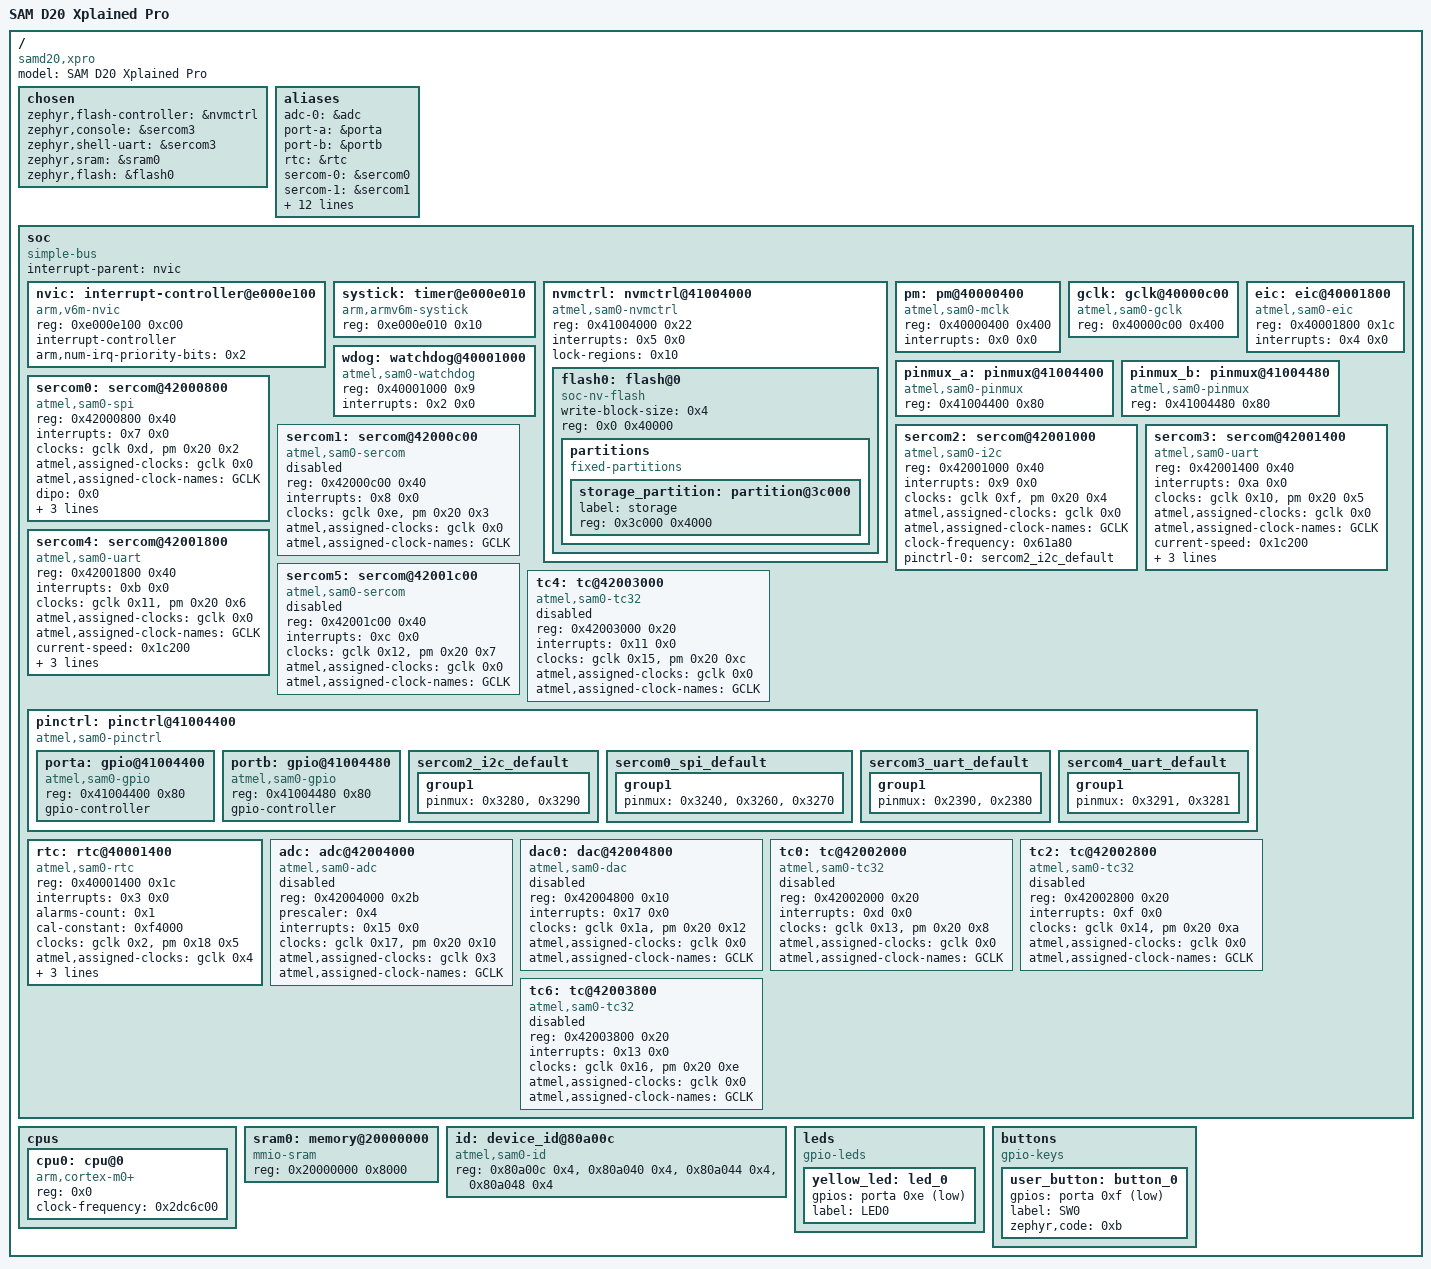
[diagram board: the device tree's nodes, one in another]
/dts-v1/;

/* node '/' defined in zephyr/dts/common/skeleton.dtsi:9 */
/ {
	#address-cells = < 0x1 >;       /* in zephyr/dts/common/skeleton.dtsi:10 */
	#size-cells = < 0x1 >;          /* in zephyr/dts/common/skeleton.dtsi:11 */
	model = "SAM D20 Xplained Pro"; /* in zephyr/boards/atmel/sam0/samd20_xpro/samd20_xpro.dts:16 */
	compatible = "samd20,xpro",
	             "atmel,samd20j18",
	             "atmel,samd20";    /* in zephyr/boards/atmel/sam0/samd20_xpro/samd20_xpro.dts:17 */

	/* node '/chosen' defined in zephyr/dts/common/skeleton.dtsi:13 */
	chosen {
		zephyr,flash-controller = &nvmctrl; /* in zephyr/dts/arm/atmel/samd2x.dtsi:37 */
		zephyr,console = &sercom3;          /* in zephyr/boards/atmel/sam0/samd20_xpro/samd20_xpro.dts:20 */
		zephyr,shell-uart = &sercom3;       /* in zephyr/boards/atmel/sam0/samd20_xpro/samd20_xpro.dts:21 */
		zephyr,sram = &sram0;               /* in zephyr/boards/atmel/sam0/samd20_xpro/samd20_xpro.dts:22 */
		zephyr,flash = &flash0;             /* in zephyr/boards/atmel/sam0/samd20_xpro/samd20_xpro.dts:23 */
	};

	/* node '/aliases' defined in zephyr/dts/common/skeleton.dtsi:15 */
	aliases {
		adc-0 = &adc;        /* in zephyr/dts/arm/atmel/samd2x.dtsi:17 */
		port-a = &porta;     /* in zephyr/dts/arm/atmel/samd2x.dtsi:19 */
		port-b = &portb;     /* in zephyr/dts/arm/atmel/samd2x.dtsi:20 */
		rtc = &rtc;          /* in zephyr/dts/arm/atmel/samd2x.dtsi:22 */
		sercom-0 = &sercom0; /* in zephyr/dts/arm/atmel/samd2x.dtsi:24 */
		sercom-1 = &sercom1; /* in zephyr/dts/arm/atmel/samd2x.dtsi:25 */
		sercom-2 = &sercom2; /* in zephyr/dts/arm/atmel/samd2x.dtsi:26 */
		sercom-3 = &sercom3; /* in zephyr/dts/arm/atmel/samd2x.dtsi:27 */
		sercom-4 = &sercom4; /* in zephyr/dts/arm/atmel/samd2x.dtsi:28 */
		sercom-5 = &sercom5; /* in zephyr/dts/arm/atmel/samd2x.dtsi:29 */
		tc-4 = &tc4;         /* in zephyr/dts/arm/atmel/samd2x.dtsi:31 */
		watchdog0 = &wdog;   /* in zephyr/dts/arm/atmel/samd2x.dtsi:33 */
		tc-0 = &tc0;         /* in zephyr/dts/arm/atmel/samd20.dtsi:12 */
		tc-2 = &tc2;         /* in zephyr/dts/arm/atmel/samd20.dtsi:13 */
		tc-6 = &tc6;         /* in zephyr/dts/arm/atmel/samd20.dtsi:14 */
		led0 = &yellow_led;  /* in zephyr/boards/atmel/sam0/samd20_xpro/samd20_xpro.dts:28 */
		sw0 = &user_button;  /* in zephyr/boards/atmel/sam0/samd20_xpro/samd20_xpro.dts:29 */
		i2c-0 = &sercom2;    /* in zephyr/boards/atmel/sam0/samd20_xpro/samd20_xpro.dts:30 */
	};

	/* node '/soc' defined in zephyr/dts/arm/armv6-m.dtsi:6 */
	soc {
		#address-cells = < 0x1 >;     /* in zephyr/dts/arm/armv6-m.dtsi:7 */
		#size-cells = < 0x1 >;        /* in zephyr/dts/arm/armv6-m.dtsi:8 */
		compatible = "simple-bus";    /* in zephyr/dts/arm/armv6-m.dtsi:9 */
		interrupt-parent = < &nvic >; /* in zephyr/dts/arm/armv6-m.dtsi:10 */
		ranges;                       /* in zephyr/dts/arm/armv6-m.dtsi:11 */

		/* node '/soc/interrupt-controller@e000e100' defined in zephyr/dts/arm/armv6-m.dtsi:13 */
		nvic: interrupt-controller@e000e100 {
			#address-cells = < 0x1 >;            /* in zephyr/dts/arm/armv6-m.dtsi:14 */
			compatible = "arm,v6m-nvic";         /* in zephyr/dts/arm/armv6-m.dtsi:15 */
			reg = < 0xe000e100 0xc00 >;          /* in zephyr/dts/arm/armv6-m.dtsi:16 */
			interrupt-controller;                /* in zephyr/dts/arm/armv6-m.dtsi:17 */
			#interrupt-cells = < 0x2 >;          /* in zephyr/dts/arm/armv6-m.dtsi:18 */
			arm,num-irq-priority-bits = < 0x2 >; /* in zephyr/dts/arm/atmel/samd2x.dtsi:223 */
			phandle = < 0x1 >;                   /* in zephyr/dts/arm/armv6-m.dtsi:10 */
		};

		/* node '/soc/timer@e000e010' defined in zephyr/dts/arm/armv6-m.dtsi:21 */
		systick: timer@e000e010 {
			compatible = "arm,armv6m-systick"; /* in zephyr/dts/arm/armv6-m.dtsi:22 */
			reg = < 0xe000e010 0x10 >;         /* in zephyr/dts/arm/armv6-m.dtsi:23 */
		};

		/* node '/soc/nvmctrl@41004000' defined in zephyr/dts/arm/atmel/samd2x.dtsi:65 */
		nvmctrl: nvmctrl@41004000 {
			compatible = "atmel,sam0-nvmctrl"; /* in zephyr/dts/arm/atmel/samd2x.dtsi:66 */
			reg = < 0x41004000 0x22 >;         /* in zephyr/dts/arm/atmel/samd2x.dtsi:67 */
			interrupts = < 0x5 0x0 >;          /* in zephyr/dts/arm/atmel/samd2x.dtsi:68 */
			#address-cells = < 0x1 >;          /* in zephyr/dts/arm/atmel/samd2x.dtsi:70 */
			#size-cells = < 0x1 >;             /* in zephyr/dts/arm/atmel/samd2x.dtsi:71 */
			lock-regions = < 0x10 >;           /* in zephyr/dts/arm/atmel/samd2x.dtsi:73 */

			/* node '/soc/nvmctrl@41004000/flash@0' defined in zephyr/dts/arm/atmel/samd2x.dtsi:75 */
			flash0: flash@0 {
				compatible = "soc-nv-flash"; /* in zephyr/dts/arm/atmel/samd2x.dtsi:76 */
				write-block-size = < 0x4 >;  /* in zephyr/dts/arm/atmel/samd2x.dtsi:78 */
				reg = < 0x0 0x40000 >;       /* in zephyr/dts/arm/atmel/samx2xx18.dtsi:14 */

				/* node '/soc/nvmctrl@41004000/flash@0/partitions' defined in zephyr/boards/atmel/sam0/samd20_xpro/samd20_xpro.dts:110 */
				partitions {
					compatible = "fixed-partitions"; /* in zephyr/boards/atmel/sam0/samd20_xpro/samd20_xpro.dts:111 */
					#address-cells = < 0x1 >;        /* in zephyr/boards/atmel/sam0/samd20_xpro/samd20_xpro.dts:112 */
					#size-cells = < 0x1 >;           /* in zephyr/boards/atmel/sam0/samd20_xpro/samd20_xpro.dts:113 */

					/* node '/soc/nvmctrl@41004000/flash@0/partitions/partition@3c000' defined in zephyr/boards/atmel/sam0/samd20_xpro/samd20_xpro.dts:120 */
					storage_partition: partition@3c000 {
						label = "storage";        /* in zephyr/boards/atmel/sam0/samd20_xpro/samd20_xpro.dts:121 */
						reg = < 0x3c000 0x4000 >; /* in zephyr/boards/atmel/sam0/samd20_xpro/samd20_xpro.dts:122 */
					};
				};
			};
		};

		/* node '/soc/pm@40000400' defined in zephyr/dts/arm/atmel/samd2x.dtsi:82 */
		pm: pm@40000400 {
			compatible = "atmel,sam0-mclk"; /* in zephyr/dts/arm/atmel/samd2x.dtsi:83 */
			reg = < 0x40000400 0x400 >;     /* in zephyr/dts/arm/atmel/samd2x.dtsi:84 */
			interrupts = < 0x0 0x0 >;       /* in zephyr/dts/arm/atmel/samd2x.dtsi:85 */
			#clock-cells = < 0x2 >;         /* in zephyr/dts/arm/atmel/samd2x.dtsi:87 */
			phandle = < 0x3 >;              /* in zephyr/dts/arm/atmel/samd20.dtsi:70 */
		};

		/* node '/soc/gclk@40000c00' defined in zephyr/dts/arm/atmel/samd2x.dtsi:90 */
		gclk: gclk@40000c00 {
			compatible = "atmel,sam0-gclk";        /* in zephyr/dts/arm/atmel/samd2x.dtsi:91 */
			reg = < 0x40000c00 0x400 >;            /* in zephyr/dts/arm/atmel/samd2x.dtsi:92 */
			#clock-cells = < 0x1 >;                /* in zephyr/dts/arm/atmel/samd2x.dtsi:94 */
			#atmel,assigned-clock-cells = < 0x1 >; /* in zephyr/dts/arm/atmel/samd2x.dtsi:95 */
			phandle = < 0x2 >;                     /* in zephyr/dts/arm/atmel/samd20.dtsi:70 */
		};

		/* node '/soc/eic@40001800' defined in zephyr/dts/arm/atmel/samd2x.dtsi:98 */
		eic: eic@40001800 {
			compatible = "atmel,sam0-eic"; /* in zephyr/dts/arm/atmel/samd2x.dtsi:99 */
			reg = < 0x40001800 0x1c >;     /* in zephyr/dts/arm/atmel/samd2x.dtsi:100 */
			interrupts = < 0x4 0x0 >;      /* in zephyr/dts/arm/atmel/samd2x.dtsi:101 */
		};

		/* node '/soc/pinmux@41004400' defined in zephyr/dts/arm/atmel/samd2x.dtsi:104 */
		pinmux_a: pinmux@41004400 {
			compatible = "atmel,sam0-pinmux"; /* in zephyr/dts/arm/atmel/samd2x.dtsi:105 */
			reg = < 0x41004400 0x80 >;        /* in zephyr/dts/arm/atmel/samd2x.dtsi:106 */
		};

		/* node '/soc/pinmux@41004480' defined in zephyr/dts/arm/atmel/samd2x.dtsi:109 */
		pinmux_b: pinmux@41004480 {
			compatible = "atmel,sam0-pinmux"; /* in zephyr/dts/arm/atmel/samd2x.dtsi:110 */
			reg = < 0x41004480 0x80 >;        /* in zephyr/dts/arm/atmel/samd2x.dtsi:111 */
		};

		/* node '/soc/watchdog@40001000' defined in zephyr/dts/arm/atmel/samd2x.dtsi:114 */
		wdog: watchdog@40001000 {
			compatible = "atmel,sam0-watchdog"; /* in zephyr/dts/arm/atmel/samd2x.dtsi:115 */
			reg = < 0x40001000 0x9 >;           /* in zephyr/dts/arm/atmel/samd2x.dtsi:116 */
			interrupts = < 0x2 0x0 >;           /* in zephyr/dts/arm/atmel/samd2x.dtsi:117 */
		};

		/* node '/soc/sercom@42000800' defined in zephyr/dts/arm/atmel/samd2x.dtsi:120 */
		sercom0: sercom@42000800 {
			reg = < 0x42000800 0x40 >;             /* in zephyr/dts/arm/atmel/samd2x.dtsi:122 */
			interrupts = < 0x7 0x0 >;              /* in zephyr/dts/arm/atmel/samd20.dtsi:69 */
			clocks = < &gclk 0xd >,
			         < &pm 0x20 0x2 >;             /* in zephyr/dts/arm/atmel/samd20.dtsi:70 */
			clock-names = "GCLK",
			              "PM";                    /* in zephyr/dts/arm/atmel/samd20.dtsi:71 */
			atmel,assigned-clocks = < &gclk 0x0 >; /* in zephyr/dts/arm/atmel/samd20.dtsi:72 */
			atmel,assigned-clock-names = "GCLK";   /* in zephyr/dts/arm/atmel/samd20.dtsi:73 */
			status = "okay";                       /* in zephyr/boards/atmel/sam0/samd20_xpro/samd20_xpro.dts:64 */
			compatible = "atmel,sam0-spi";         /* in zephyr/boards/atmel/sam0/samd20_xpro/samd20_xpro.dts:65 */
			dipo = < 0x0 >;                        /* in zephyr/boards/atmel/sam0/samd20_xpro/samd20_xpro.dts:66 */
			dopo = < 0x1 >;                        /* in zephyr/boards/atmel/sam0/samd20_xpro/samd20_xpro.dts:67 */
			#address-cells = < 0x1 >;              /* in zephyr/boards/atmel/sam0/samd20_xpro/samd20_xpro.dts:68 */
			#size-cells = < 0x0 >;                 /* in zephyr/boards/atmel/sam0/samd20_xpro/samd20_xpro.dts:69 */
			cs-gpios = < &porta 0x5 0x1 >;         /* in zephyr/boards/atmel/sam0/samd20_xpro/samd20_xpro.dts:70 */
			pinctrl-0 = < &sercom0_spi_default >;  /* in zephyr/boards/atmel/sam0/samd20_xpro/samd20_xpro.dts:72 */
			pinctrl-names = "default";             /* in zephyr/boards/atmel/sam0/samd20_xpro/samd20_xpro.dts:73 */
		};

		/* node '/soc/sercom@42000c00' defined in zephyr/dts/arm/atmel/samd2x.dtsi:126 */
		sercom1: sercom@42000c00 {
			compatible = "atmel,sam0-sercom";      /* in zephyr/dts/arm/atmel/samd2x.dtsi:127 */
			reg = < 0x42000c00 0x40 >;             /* in zephyr/dts/arm/atmel/samd2x.dtsi:128 */
			status = "disabled";                   /* in zephyr/dts/arm/atmel/samd2x.dtsi:129 */
			interrupts = < 0x8 0x0 >;              /* in zephyr/dts/arm/atmel/samd20.dtsi:77 */
			clocks = < &gclk 0xe >,
			         < &pm 0x20 0x3 >;             /* in zephyr/dts/arm/atmel/samd20.dtsi:78 */
			clock-names = "GCLK",
			              "PM";                    /* in zephyr/dts/arm/atmel/samd20.dtsi:79 */
			atmel,assigned-clocks = < &gclk 0x0 >; /* in zephyr/dts/arm/atmel/samd20.dtsi:80 */
			atmel,assigned-clock-names = "GCLK";   /* in zephyr/dts/arm/atmel/samd20.dtsi:81 */
		};

		/* node '/soc/sercom@42001000' defined in zephyr/dts/arm/atmel/samd2x.dtsi:132 */
		sercom2: sercom@42001000 {
			reg = < 0x42001000 0x40 >;             /* in zephyr/dts/arm/atmel/samd2x.dtsi:134 */
			interrupts = < 0x9 0x0 >;              /* in zephyr/dts/arm/atmel/samd20.dtsi:85 */
			clocks = < &gclk 0xf >,
			         < &pm 0x20 0x4 >;             /* in zephyr/dts/arm/atmel/samd20.dtsi:86 */
			clock-names = "GCLK",
			              "PM";                    /* in zephyr/dts/arm/atmel/samd20.dtsi:87 */
			atmel,assigned-clocks = < &gclk 0x0 >; /* in zephyr/dts/arm/atmel/samd20.dtsi:88 */
			atmel,assigned-clock-names = "GCLK";   /* in zephyr/dts/arm/atmel/samd20.dtsi:89 */
			status = "okay";                       /* in zephyr/boards/atmel/sam0/samd20_xpro/samd20_xpro.dts:77 */
			compatible = "atmel,sam0-i2c";         /* in zephyr/boards/atmel/sam0/samd20_xpro/samd20_xpro.dts:78 */
			clock-frequency = < 0x61a80 >;         /* in zephyr/boards/atmel/sam0/samd20_xpro/samd20_xpro.dts:79 */
			#address-cells = < 0x1 >;              /* in zephyr/boards/atmel/sam0/samd20_xpro/samd20_xpro.dts:80 */
			#size-cells = < 0x0 >;                 /* in zephyr/boards/atmel/sam0/samd20_xpro/samd20_xpro.dts:81 */
			pinctrl-0 = < &sercom2_i2c_default >;  /* in zephyr/boards/atmel/sam0/samd20_xpro/samd20_xpro.dts:83 */
			pinctrl-names = "default";             /* in zephyr/boards/atmel/sam0/samd20_xpro/samd20_xpro.dts:84 */
		};

		/* node '/soc/sercom@42001400' defined in zephyr/dts/arm/atmel/samd2x.dtsi:138 */
		sercom3: sercom@42001400 {
			reg = < 0x42001400 0x40 >;             /* in zephyr/dts/arm/atmel/samd2x.dtsi:140 */
			interrupts = < 0xa 0x0 >;              /* in zephyr/dts/arm/atmel/samd20.dtsi:93 */
			clocks = < &gclk 0x10 >,
			         < &pm 0x20 0x5 >;             /* in zephyr/dts/arm/atmel/samd20.dtsi:94 */
			clock-names = "GCLK",
			              "PM";                    /* in zephyr/dts/arm/atmel/samd20.dtsi:95 */
			atmel,assigned-clocks = < &gclk 0x0 >; /* in zephyr/dts/arm/atmel/samd20.dtsi:96 */
			atmel,assigned-clock-names = "GCLK";   /* in zephyr/dts/arm/atmel/samd20.dtsi:97 */
			status = "okay";                       /* in zephyr/boards/atmel/sam0/samd20_xpro/samd20_xpro.dts:88 */
			compatible = "atmel,sam0-uart";        /* in zephyr/boards/atmel/sam0/samd20_xpro/samd20_xpro.dts:89 */
			current-speed = < 0x1c200 >;           /* in zephyr/boards/atmel/sam0/samd20_xpro/samd20_xpro.dts:90 */
			rxpo = < 0x3 >;                        /* in zephyr/boards/atmel/sam0/samd20_xpro/samd20_xpro.dts:91 */
			txpo = < 0x1 >;                        /* in zephyr/boards/atmel/sam0/samd20_xpro/samd20_xpro.dts:92 */
			pinctrl-0 = < &sercom3_uart_default >; /* in zephyr/boards/atmel/sam0/samd20_xpro/samd20_xpro.dts:94 */
			pinctrl-names = "default";             /* in zephyr/boards/atmel/sam0/samd20_xpro/samd20_xpro.dts:95 */
		};

		/* node '/soc/sercom@42001800' defined in zephyr/dts/arm/atmel/samd2x.dtsi:144 */
		sercom4: sercom@42001800 {
			reg = < 0x42001800 0x40 >;             /* in zephyr/dts/arm/atmel/samd2x.dtsi:146 */
			interrupts = < 0xb 0x0 >;              /* in zephyr/dts/arm/atmel/samd20.dtsi:101 */
			clocks = < &gclk 0x11 >,
			         < &pm 0x20 0x6 >;             /* in zephyr/dts/arm/atmel/samd20.dtsi:102 */
			clock-names = "GCLK",
			              "PM";                    /* in zephyr/dts/arm/atmel/samd20.dtsi:103 */
			atmel,assigned-clocks = < &gclk 0x0 >; /* in zephyr/dts/arm/atmel/samd20.dtsi:104 */
			atmel,assigned-clock-names = "GCLK";   /* in zephyr/dts/arm/atmel/samd20.dtsi:105 */
			status = "okay";                       /* in zephyr/boards/atmel/sam0/samd20_xpro/samd20_xpro.dts:99 */
			compatible = "atmel,sam0-uart";        /* in zephyr/boards/atmel/sam0/samd20_xpro/samd20_xpro.dts:100 */
			current-speed = < 0x1c200 >;           /* in zephyr/boards/atmel/sam0/samd20_xpro/samd20_xpro.dts:101 */
			rxpo = < 0x1 >;                        /* in zephyr/boards/atmel/sam0/samd20_xpro/samd20_xpro.dts:102 */
			txpo = < 0x0 >;                        /* in zephyr/boards/atmel/sam0/samd20_xpro/samd20_xpro.dts:103 */
			pinctrl-0 = < &sercom4_uart_default >; /* in zephyr/boards/atmel/sam0/samd20_xpro/samd20_xpro.dts:105 */
			pinctrl-names = "default";             /* in zephyr/boards/atmel/sam0/samd20_xpro/samd20_xpro.dts:106 */
		};

		/* node '/soc/sercom@42001c00' defined in zephyr/dts/arm/atmel/samd2x.dtsi:150 */
		sercom5: sercom@42001c00 {
			compatible = "atmel,sam0-sercom";      /* in zephyr/dts/arm/atmel/samd2x.dtsi:151 */
			reg = < 0x42001c00 0x40 >;             /* in zephyr/dts/arm/atmel/samd2x.dtsi:152 */
			status = "disabled";                   /* in zephyr/dts/arm/atmel/samd2x.dtsi:153 */
			interrupts = < 0xc 0x0 >;              /* in zephyr/dts/arm/atmel/samd20.dtsi:109 */
			clocks = < &gclk 0x12 >,
			         < &pm 0x20 0x7 >;             /* in zephyr/dts/arm/atmel/samd20.dtsi:110 */
			clock-names = "GCLK",
			              "PM";                    /* in zephyr/dts/arm/atmel/samd20.dtsi:111 */
			atmel,assigned-clocks = < &gclk 0x0 >; /* in zephyr/dts/arm/atmel/samd20.dtsi:112 */
			atmel,assigned-clock-names = "GCLK";   /* in zephyr/dts/arm/atmel/samd20.dtsi:113 */
		};

		/* node '/soc/tc@42003000' defined in zephyr/dts/arm/atmel/samd2x.dtsi:156 */
		tc4: tc@42003000 {
			compatible = "atmel,sam0-tc32";        /* in zephyr/dts/arm/atmel/samd2x.dtsi:157 */
			reg = < 0x42003000 0x20 >;             /* in zephyr/dts/arm/atmel/samd2x.dtsi:158 */
			status = "disabled";                   /* in zephyr/dts/arm/atmel/samd2x.dtsi:159 */
			interrupts = < 0x11 0x0 >;             /* in zephyr/dts/arm/atmel/samd20.dtsi:117 */
			clocks = < &gclk 0x15 >,
			         < &pm 0x20 0xc >;             /* in zephyr/dts/arm/atmel/samd20.dtsi:118 */
			clock-names = "GCLK",
			              "PM";                    /* in zephyr/dts/arm/atmel/samd20.dtsi:119 */
			atmel,assigned-clocks = < &gclk 0x0 >; /* in zephyr/dts/arm/atmel/samd20.dtsi:120 */
			atmel,assigned-clock-names = "GCLK";   /* in zephyr/dts/arm/atmel/samd20.dtsi:121 */
		};

		/* node '/soc/pinctrl@41004400' defined in zephyr/dts/arm/atmel/samd2x.dtsi:162 */
		pinctrl: pinctrl@41004400 {
			compatible = "atmel,sam0-pinctrl";        /* in zephyr/dts/arm/atmel/samd2x.dtsi:163 */
			ranges = < 0x41004400 0x41004400 0x100 >; /* in zephyr/dts/arm/atmel/samd2x.dtsi:164 */
			#address-cells = < 0x1 >;                 /* in zephyr/dts/arm/atmel/samd2x.dtsi:166 */
			#size-cells = < 0x1 >;                    /* in zephyr/dts/arm/atmel/samd2x.dtsi:167 */

			/* node '/soc/pinctrl@41004400/gpio@41004400' defined in zephyr/dts/arm/atmel/samd2x.dtsi:169 */
			porta: gpio@41004400 {
				compatible = "atmel,sam0-gpio"; /* in zephyr/dts/arm/atmel/samd2x.dtsi:170 */
				reg = < 0x41004400 0x80 >;      /* in zephyr/dts/arm/atmel/samd2x.dtsi:171 */
				#atmel,pin-cells = < 0x2 >;     /* in zephyr/dts/arm/atmel/samd2x.dtsi:173 */
				#gpio-cells = < 0x2 >;          /* in zephyr/dts/arm/atmel/samd2x.dtsi:174 */
				gpio-controller;                /* in zephyr/dts/arm/atmel/samd2x.dtsi:176 */
				phandle = < 0x4 >;              /* in zephyr/boards/atmel/sam0/samd20_xpro/samd20_xpro.dts:70 */
			};

			/* node '/soc/pinctrl@41004400/gpio@41004480' defined in zephyr/dts/arm/atmel/samd2x.dtsi:179 */
			portb: gpio@41004480 {
				compatible = "atmel,sam0-gpio"; /* in zephyr/dts/arm/atmel/samd2x.dtsi:180 */
				reg = < 0x41004480 0x80 >;      /* in zephyr/dts/arm/atmel/samd2x.dtsi:181 */
				#atmel,pin-cells = < 0x2 >;     /* in zephyr/dts/arm/atmel/samd2x.dtsi:183 */
				#gpio-cells = < 0x2 >;          /* in zephyr/dts/arm/atmel/samd2x.dtsi:184 */
				gpio-controller;                /* in zephyr/dts/arm/atmel/samd2x.dtsi:186 */
			};

			/* node '/soc/pinctrl@41004400/sercom2_i2c_default' defined in zephyr/boards/atmel/sam0/samd20_xpro/samd20_xpro-pinctrl.dtsi:9 */
			sercom2_i2c_default: sercom2_i2c_default {
				phandle = < 0x6 >; /* in zephyr/boards/atmel/sam0/samd20_xpro/samd20_xpro.dts:83 */

				/* node '/soc/pinctrl@41004400/sercom2_i2c_default/group1' defined in zephyr/boards/atmel/sam0/samd20_xpro/samd20_xpro-pinctrl.dtsi:10 */
				group1 {
					pinmux = < 0x3280 >,
					         < 0x3290 >; /* in zephyr/boards/atmel/sam0/samd20_xpro/samd20_xpro-pinctrl.dtsi:11 */
				};
			};

			/* node '/soc/pinctrl@41004400/sercom0_spi_default' defined in zephyr/boards/atmel/sam0/samd20_xpro/samd20_xpro-pinctrl.dtsi:16 */
			sercom0_spi_default: sercom0_spi_default {
				phandle = < 0x5 >; /* in zephyr/boards/atmel/sam0/samd20_xpro/samd20_xpro.dts:72 */

				/* node '/soc/pinctrl@41004400/sercom0_spi_default/group1' defined in zephyr/boards/atmel/sam0/samd20_xpro/samd20_xpro-pinctrl.dtsi:17 */
				group1 {
					pinmux = < 0x3240 >,
					         < 0x3260 >,
					         < 0x3270 >; /* in zephyr/boards/atmel/sam0/samd20_xpro/samd20_xpro-pinctrl.dtsi:18 */
				};
			};

			/* node '/soc/pinctrl@41004400/sercom3_uart_default' defined in zephyr/boards/atmel/sam0/samd20_xpro/samd20_xpro-pinctrl.dtsi:24 */
			sercom3_uart_default: sercom3_uart_default {
				phandle = < 0x7 >; /* in zephyr/boards/atmel/sam0/samd20_xpro/samd20_xpro.dts:94 */

				/* node '/soc/pinctrl@41004400/sercom3_uart_default/group1' defined in zephyr/boards/atmel/sam0/samd20_xpro/samd20_xpro-pinctrl.dtsi:25 */
				group1 {
					pinmux = < 0x2390 >,
					         < 0x2380 >; /* in zephyr/boards/atmel/sam0/samd20_xpro/samd20_xpro-pinctrl.dtsi:26 */
				};
			};

			/* node '/soc/pinctrl@41004400/sercom4_uart_default' defined in zephyr/boards/atmel/sam0/samd20_xpro/samd20_xpro-pinctrl.dtsi:31 */
			sercom4_uart_default: sercom4_uart_default {
				phandle = < 0x8 >; /* in zephyr/boards/atmel/sam0/samd20_xpro/samd20_xpro.dts:105 */

				/* node '/soc/pinctrl@41004400/sercom4_uart_default/group1' defined in zephyr/boards/atmel/sam0/samd20_xpro/samd20_xpro-pinctrl.dtsi:32 */
				group1 {
					pinmux = < 0x3291 >,
					         < 0x3281 >; /* in zephyr/boards/atmel/sam0/samd20_xpro/samd20_xpro-pinctrl.dtsi:33 */
				};
			};
		};

		/* node '/soc/rtc@40001400' defined in zephyr/dts/arm/atmel/samd2x.dtsi:190 */
		rtc: rtc@40001400 {
			compatible = "atmel,sam0-rtc";         /* in zephyr/dts/arm/atmel/samd2x.dtsi:191 */
			reg = < 0x40001400 0x1c >;             /* in zephyr/dts/arm/atmel/samd2x.dtsi:192 */
			interrupts = < 0x3 0x0 >;              /* in zephyr/dts/arm/atmel/samd2x.dtsi:193 */
			alarms-count = < 0x1 >;                /* in zephyr/dts/arm/atmel/samd2x.dtsi:198 */
			cal-constant = < 0xf4000 >;            /* in zephyr/dts/arm/atmel/samd2x.dtsi:199 */
			clocks = < &gclk 0x2 >,
			         < &pm 0x18 0x5 >;             /* in zephyr/dts/arm/atmel/samd20.dtsi:62 */
			clock-names = "GCLK",
			              "PM";                    /* in zephyr/dts/arm/atmel/samd20.dtsi:63 */
			atmel,assigned-clocks = < &gclk 0x4 >; /* in zephyr/dts/arm/atmel/samd20.dtsi:64 */
			atmel,assigned-clock-names = "GCLK";   /* in zephyr/dts/arm/atmel/samd20.dtsi:65 */
			status = "okay";                       /* in zephyr/boards/atmel/sam0/samd20_xpro/samd20_xpro.dts:58 */
			counter-mode = "clock";                /* in zephyr/boards/atmel/sam0/samd20_xpro/samd20_xpro.dts:59 */
			prescaler = < 0x400 >;                 /* in zephyr/boards/atmel/sam0/samd20_xpro/samd20_xpro.dts:60 */
		};

		/* node '/soc/adc@42004000' defined in zephyr/dts/arm/atmel/samd2x.dtsi:202 */
		adc: adc@42004000 {
			compatible = "atmel,sam0-adc";         /* in zephyr/dts/arm/atmel/samd2x.dtsi:203 */
			reg = < 0x42004000 0x2b >;             /* in zephyr/dts/arm/atmel/samd2x.dtsi:204 */
			status = "disabled";                   /* in zephyr/dts/arm/atmel/samd2x.dtsi:205 */
			#io-channel-cells = < 0x1 >;           /* in zephyr/dts/arm/atmel/samd2x.dtsi:207 */
			prescaler = < 0x4 >;                   /* in zephyr/dts/arm/atmel/samd2x.dtsi:209 */
			interrupts = < 0x15 0x0 >;             /* in zephyr/dts/arm/atmel/samd20.dtsi:125 */
			interrupt-names = "resrdy";            /* in zephyr/dts/arm/atmel/samd20.dtsi:126 */
			clocks = < &gclk 0x17 >,
			         < &pm 0x20 0x10 >;            /* in zephyr/dts/arm/atmel/samd20.dtsi:127 */
			clock-names = "GCLK",
			              "PM";                    /* in zephyr/dts/arm/atmel/samd20.dtsi:128 */
			atmel,assigned-clocks = < &gclk 0x3 >; /* in zephyr/dts/arm/atmel/samd20.dtsi:134 */
			atmel,assigned-clock-names = "GCLK";   /* in zephyr/dts/arm/atmel/samd20.dtsi:135 */
		};

		/* node '/soc/dac@42004800' defined in zephyr/dts/arm/atmel/samd2x.dtsi:212 */
		dac0: dac@42004800 {
			compatible = "atmel,sam0-dac";         /* in zephyr/dts/arm/atmel/samd2x.dtsi:213 */
			reg = < 0x42004800 0x10 >;             /* in zephyr/dts/arm/atmel/samd2x.dtsi:214 */
			status = "disabled";                   /* in zephyr/dts/arm/atmel/samd2x.dtsi:215 */
			#io-channel-cells = < 0x0 >;           /* in zephyr/dts/arm/atmel/samd2x.dtsi:217 */
			interrupts = < 0x17 0x0 >;             /* in zephyr/dts/arm/atmel/samd20.dtsi:54 */
			clocks = < &gclk 0x1a >,
			         < &pm 0x20 0x12 >;            /* in zephyr/dts/arm/atmel/samd20.dtsi:55 */
			clock-names = "GCLK",
			              "PM";                    /* in zephyr/dts/arm/atmel/samd20.dtsi:56 */
			atmel,assigned-clocks = < &gclk 0x0 >; /* in zephyr/dts/arm/atmel/samd20.dtsi:57 */
			atmel,assigned-clock-names = "GCLK";   /* in zephyr/dts/arm/atmel/samd20.dtsi:58 */
		};

		/* node '/soc/tc@42002000' defined in zephyr/dts/arm/atmel/samd20.dtsi:18 */
		tc0: tc@42002000 {
			compatible = "atmel,sam0-tc32";        /* in zephyr/dts/arm/atmel/samd20.dtsi:19 */
			reg = < 0x42002000 0x20 >;             /* in zephyr/dts/arm/atmel/samd20.dtsi:20 */
			interrupts = < 0xd 0x0 >;              /* in zephyr/dts/arm/atmel/samd20.dtsi:21 */
			clocks = < &gclk 0x13 >,
			         < &pm 0x20 0x8 >;             /* in zephyr/dts/arm/atmel/samd20.dtsi:22 */
			clock-names = "GCLK",
			              "PM";                    /* in zephyr/dts/arm/atmel/samd20.dtsi:23 */
			atmel,assigned-clocks = < &gclk 0x0 >; /* in zephyr/dts/arm/atmel/samd20.dtsi:24 */
			atmel,assigned-clock-names = "GCLK";   /* in zephyr/dts/arm/atmel/samd20.dtsi:25 */
			status = "disabled";                   /* in zephyr/dts/arm/atmel/samd20.dtsi:26 */
		};

		/* node '/soc/tc@42002800' defined in zephyr/dts/arm/atmel/samd20.dtsi:29 */
		tc2: tc@42002800 {
			compatible = "atmel,sam0-tc32";        /* in zephyr/dts/arm/atmel/samd20.dtsi:30 */
			reg = < 0x42002800 0x20 >;             /* in zephyr/dts/arm/atmel/samd20.dtsi:31 */
			interrupts = < 0xf 0x0 >;              /* in zephyr/dts/arm/atmel/samd20.dtsi:32 */
			clocks = < &gclk 0x14 >,
			         < &pm 0x20 0xa >;             /* in zephyr/dts/arm/atmel/samd20.dtsi:33 */
			clock-names = "GCLK",
			              "PM";                    /* in zephyr/dts/arm/atmel/samd20.dtsi:34 */
			atmel,assigned-clocks = < &gclk 0x0 >; /* in zephyr/dts/arm/atmel/samd20.dtsi:35 */
			atmel,assigned-clock-names = "GCLK";   /* in zephyr/dts/arm/atmel/samd20.dtsi:36 */
			status = "disabled";                   /* in zephyr/dts/arm/atmel/samd20.dtsi:37 */
		};

		/* node '/soc/tc@42003800' defined in zephyr/dts/arm/atmel/samd20.dtsi:40 */
		tc6: tc@42003800 {
			compatible = "atmel,sam0-tc32";        /* in zephyr/dts/arm/atmel/samd20.dtsi:41 */
			reg = < 0x42003800 0x20 >;             /* in zephyr/dts/arm/atmel/samd20.dtsi:42 */
			interrupts = < 0x13 0x0 >;             /* in zephyr/dts/arm/atmel/samd20.dtsi:43 */
			clocks = < &gclk 0x16 >,
			         < &pm 0x20 0xe >;             /* in zephyr/dts/arm/atmel/samd20.dtsi:44 */
			clock-names = "GCLK",
			              "PM";                    /* in zephyr/dts/arm/atmel/samd20.dtsi:45 */
			atmel,assigned-clocks = < &gclk 0x0 >; /* in zephyr/dts/arm/atmel/samd20.dtsi:46 */
			atmel,assigned-clock-names = "GCLK";   /* in zephyr/dts/arm/atmel/samd20.dtsi:47 */
			status = "disabled";                   /* in zephyr/dts/arm/atmel/samd20.dtsi:48 */
		};
	};

	/* node '/cpus' defined in zephyr/dts/arm/atmel/samd2x.dtsi:40 */
	cpus {
		#address-cells = < 0x1 >; /* in zephyr/dts/arm/atmel/samd2x.dtsi:41 */
		#size-cells = < 0x0 >;    /* in zephyr/dts/arm/atmel/samd2x.dtsi:42 */

		/* node '/cpus/cpu@0' defined in zephyr/dts/arm/atmel/samd2x.dtsi:44 */
		cpu0: cpu@0 {
			compatible = "arm,cortex-m0+";   /* in zephyr/dts/arm/atmel/samd2x.dtsi:45 */
			reg = < 0x0 >;                   /* in zephyr/dts/arm/atmel/samd2x.dtsi:46 */
			device_type = "cpu";             /* in zephyr/dts/arm/atmel/samd2x.dtsi:48 */
			clock-frequency = < 0x2dc6c00 >; /* in zephyr/boards/atmel/sam0/samd20_xpro/samd20_xpro.dts:54 */
		};
	};

	/* node '/memory@20000000' defined in zephyr/dts/arm/atmel/samd2x.dtsi:52 */
	sram0: memory@20000000 {
		compatible = "mmio-sram";    /* in zephyr/dts/arm/atmel/samd2x.dtsi:53 */
		reg = < 0x20000000 0x8000 >; /* in zephyr/dts/arm/atmel/samx2xx18.dtsi:10 */
	};

	/* node '/device_id@80a00c' defined in zephyr/dts/arm/atmel/samd2x.dtsi:56 */
	id: device_id@80a00c {
		compatible = "atmel,sam0-id"; /* in zephyr/dts/arm/atmel/samd2x.dtsi:57 */
		reg = < 0x80a00c 0x4 >,
		      < 0x80a040 0x4 >,
		      < 0x80a044 0x4 >,
		      < 0x80a048 0x4 >;       /* in zephyr/dts/arm/atmel/samd2x.dtsi:58 */
	};

	/* node '/leds' defined in zephyr/boards/atmel/sam0/samd20_xpro/samd20_xpro.dts:33 */
	leds {
		compatible = "gpio-leds"; /* in zephyr/boards/atmel/sam0/samd20_xpro/samd20_xpro.dts:34 */

		/* node '/leds/led_0' defined in zephyr/boards/atmel/sam0/samd20_xpro/samd20_xpro.dts:36 */
		yellow_led: led_0 {
			gpios = < &porta 0xe 0x1 >; /* in zephyr/boards/atmel/sam0/samd20_xpro/samd20_xpro.dts:37 */
			label = "LED0";             /* in zephyr/boards/atmel/sam0/samd20_xpro/samd20_xpro.dts:38 */
		};
	};

	/* node '/buttons' defined in zephyr/boards/atmel/sam0/samd20_xpro/samd20_xpro.dts:42 */
	buttons {
		compatible = "gpio-keys"; /* in zephyr/boards/atmel/sam0/samd20_xpro/samd20_xpro.dts:43 */

		/* node '/buttons/button_0' defined in zephyr/boards/atmel/sam0/samd20_xpro/samd20_xpro.dts:45 */
		user_button: button_0 {
			gpios = < &porta 0xf 0x11 >; /* in zephyr/boards/atmel/sam0/samd20_xpro/samd20_xpro.dts:46 */
			label = "SW0";               /* in zephyr/boards/atmel/sam0/samd20_xpro/samd20_xpro.dts:47 */
			zephyr,code = < 0xb >;       /* in zephyr/boards/atmel/sam0/samd20_xpro/samd20_xpro.dts:48 */
		};
	};
};
